# SIM3U166_B register map
File version: 1
CPU: 
Registers are 32-bit, read-write, reset 0x0 unless marked. A register's access mark holds for its fields unless they carry their own. Offsets are from the block's base; [hi:lo] are bit positions; {n}, {i} and the like mark numbered series; 'fields as' and 'values as' point back to an identical list.

## USB_0
Base 0x40018000
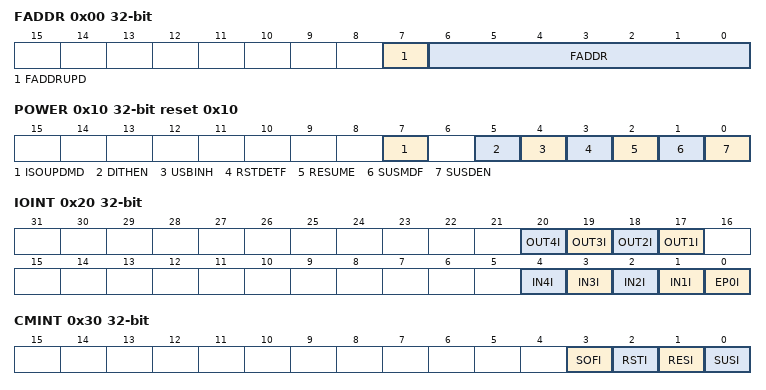
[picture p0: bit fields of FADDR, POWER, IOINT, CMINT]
0x00 FADDR — Function Address
  [7] FADDRUPD ro — Function Address Update.
    0=NOT_SET (The last address written to FADDR is in effect.); 1=SET (The last address written to FADDR is not yet in effect.)
  [6:0] FADDR — Function Address.
0x10 POWER reset 0x10 — Power Control
  [7] ISOUPDMD — ISO Update Mode.
    0=SEND_ON_IN (When software writes IPRDYI = 1, USB will send the packet when the next IN token is received.); 1=SEND_ON_SOF (When software writes IPRDYI = 1, USB will wait for a SOF token before sending the packet. If an IN token is received before a SOF token, USB will send a zero-length data packet.)
  [5] DITHEN — USB Dither Enable.
    0=DISABLED (Disable automatic USB dithering.); 1=ENABLED (Enable automatic USB dithering.)
  [4] USBINH — USB Inhibit.
    0=INACTIVE (Enable the USB module.); 1=ACTIVE (USB module inhibited. All USB traffic is ignored.)
  [3] RSTDETF ro — Reset Detect Flag.
    0=NOT_SET (Reset signaling is not present on the bus.); 1=SET (Reset signaling detected on the bus.)
  [2] RESUME — Force Resume.
    0=STOP; 1=GENERATE
  [1] SUSMDF ro — Suspend Mode Flag.
    0=NOT_SET (The USB module is not in suspend mode.); 1=SET (The USB module is in suspend mode.)
  [0] SUSDEN — Suspend Detection Enable.
    0=DISABLED (Disable suspend detection. The USB module will ignore suspend signaling on the bus.); 1=ENABLED (Enable suspend detection. The USB module will enter suspend mode if it detects suspend signalling on the bus.)
0x20 IOINT — IN/OUT Endpoint Interrupt Flags
  [n+16] OUT{n}I (n=1..4) — OUT Endpoint {n} Interrupt Flag.
    0=NOT_SET (Read: OUT Endpoint {n} interrupt has not occurred. Write: No effect.); 1=SET (Read: OUT Endpoint {n} interrupt occurred. Write: Clear the interrupt.)
  [n] IN{n}I (n=1..4) — IN Endpoint {n} Interrupt Flag.
    0=NOT_SET (Read: IN Endpoint {n} interrupt has not occurred. Write: No effect.); 1=SET (Read: IN Endpoint {n} interrupt occurred. Write: Clear the interrupt.)
  [0] EP0I — Endpoint 0 Interrupt Flag.
    0=NOT_SET (Read: Endpoint 0 interrupt has not occurred. Write: No effect.); 1=SET (Read: Endpoint 0 interrupt occurred. Write: Clear the interrupt.)
0x30 CMINT — Common Interrupt Flags
  [3] SOFI — Start of Frame Interrupt Flag.
    0=NOT_SET (Read: SOF interrupt has not occurred. Write: No effect.); 1=SET (Read: SOF interrupt occurred. Write: Clear the interrupt.)
  [2] RSTI — Reset Interrupt Flag.
    0=NOT_SET (Read: Reset interrupt has not occurred. Write: No effect.); 1=SET (Read: Reset interrupt occurred. Write: Clear the interrupt.)
  [1] RESI — Resume Interrupt Flag.
    0=NOT_SET (Read: Resume interrupt has not occurred. Write: No effect.); 1=SET (Read: Resume interrupt occurred. Write: Clear the interrupt.)
  [0] SUSI — Suspend Interrupt Flag.
    0=NOT_SET (Read: Suspend interrupt has not occurred. Write: No effect.); 1=SET (Read: Suspend interrupt occurred. Write: Clear the interrupt.)
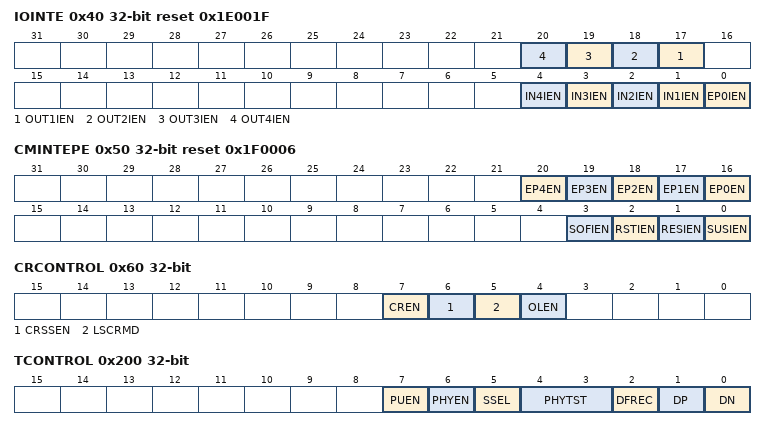
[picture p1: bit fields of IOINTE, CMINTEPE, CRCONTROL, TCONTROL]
0x40 IOINTE reset 0x1E001F — IN/OUT Endpoint Interrupt Control
  [n+16] OUT{n}IEN (n=1..4) — OUT Endpoint {n} Interrupt Enable.
    0=DISABLED (Disable the OUT Endpoint {n} interrupt.); 1=ENABLED (Enable the OUT Endpoint {n} interrupt.)
  [n] IN{n}IEN (n=1..4) — IN Endpoint {n} Interrupt Enable.
    0=DISABLED (Disable the IN Endpoint {n} interrupt.); 1=ENABLED (Enable the IN Endpoint {n} interrupt.)
  [0] EP0IEN — Endpoint 0 Interrupt Enable.
    0=DISABLED (Disable the Endpoint 0 interrupt.); 1=ENABLED (Enable the Endpoint 0 interrupt.)
0x50 CMINTEPE reset 0x1F0006 — Common Interrupt and Endpoint Control
  [n+16] EP{n}EN (n=0..4) — Endpoint {n} Enable.
    0=DISABLED (Disable Endpoint {n} (no NACK, ACK, or STALL on the USB network).); 1=ENABLED (Enable Endpoint {n} (normal).)
  [3] SOFIEN — Start of Frame Interrupt Enable.
    0=DISABLED (Disable the SOF interrupt.); 1=ENABLED (Enable the SOF interrupt.)
  [2] RSTIEN — Reset Interrupt Enable.
    0=DISABLED (Disable the Reset interrupt.); 1=ENABLED (Enable the Reset interrupt.)
  [1] RESIEN — Resume Interrupt Enable.
    0=DISABLED (Disable the Resume interrupt.); 1=ENABLED (Enable the Resume interrupt.)
  [0] SUSIEN — Suspend Interrupt Enable.
    0=DISABLED (Disable the Suspend interrupt.); 1=ENABLED (Enable the Suspend interrupt.)
0x60 CRCONTROL — Clock Recovery Control
  [7] CREN — Clock Recovery Enable.
    0=DISABLED (Disable clock recovery.); 1=ENABLED (Enable clock recovery.)
  [6] CRSSEN — Clock Recovery Single Step Enable.
    0=DISABLED (Normal calibration mode.); 1=ENABLED (Single step mode.)
  [5] LSCRMD — Low Speed Clock Recovery Mode.
    0=FULL_SPEED (Full Speed Mode.); 1=LOW_SPEED (Low Speed Mode.)
  [4] OLEN — Oscillator Open-Loop Mode Enable.
    0=DISABLED (Do not freeze the USB oscillator output frequency (closed loop mode).); 1=ENABLED (Freeze the USB oscillator output frequency (open loop mode).)
0x70 FRAME — Frame Number
  [10:0] FRAMENUM ro — Frame Number.
0x200 TCONTROL — Transceiver Control
  [7] PUEN — Internal Pull-up Resistor Enable.
    0=DISABLED (Disable the internal pull-up resistor (device effectively detached from the USB network).); 1=ENABLED (Enable the internal pull-up resistor when VBUS is present (device is attached to the USB network).)
  [6] PHYEN — Physical Layer Enable.
    0=DISABLED (Disable the USB physical layer Transceiver (suspend).); 1=ENABLED (Enable the USB physical layer Transceiver (normal).)
  [5] SSEL — USB Speed Select.
    0=LOW_SPEED (USB operates as a Low Speed device. If enabled, the internal pull-up resistor appears on the D- line.); 1=FULL_SPEED (USB operates as a Full Speed device. If enabled, the internal pull-up resistor appears on the D+ line.)
  [4:3] PHYTST — Physical Layer Test.
    0=MODE0 (Mode 0: Normal (non-test mode) (D+ = X, D- = X).); 1=MODE1 (Mode 1: Differential 1 Forced (D+ = 1, D- = 0).); 2=MODE2 (Mode 2: Differential 0 Forced (D+ = 0, D- = 1).); 3=MODE3 (Mode 3: Single-Ended 0 Forced (D+ = 0, D- = 0).)
  [2] DFREC ro — Differential Receiver State.
    0=DIFF_0 (Differential 0 signalling is present on the bus.); 1=DIFF_1 (Differential 1 signalling is present on the bus.)
  [1] DP ro — D+ Signal State.
    0=LOGIC_0 (D+ signal currently at logic 0.); 1=LOGIC_1 (D+ signal currently at logic 1.)
  [0] DN ro — D- Signal State.
    0=LOGIC_0 (D- signal currently at logic 0.); 1=LOGIC_1 (D- signal currently at logic 1.)
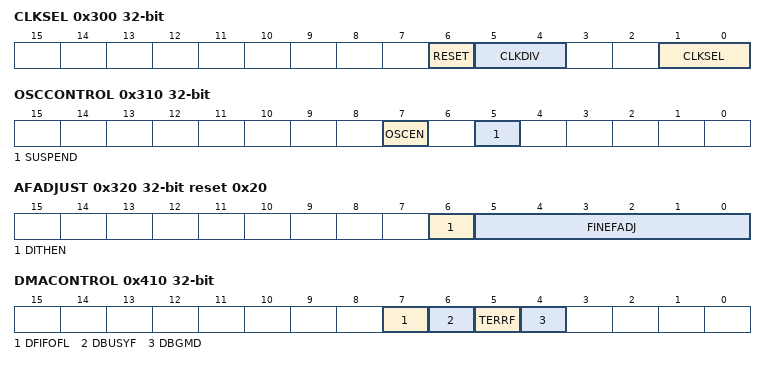
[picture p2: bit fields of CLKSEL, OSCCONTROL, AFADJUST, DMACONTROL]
0x300 CLKSEL — Module Clock Select
  [6] RESET wo — USB Reset.
    0=NOT_SET (Do not reset the USB module.); 1=SET (Reset the USB module.)
  [5:4] CLKDIV — USB Clock Divider.
    0=DIV1 (The USB module uses the selected input clock divided by 1.); 1=DIV2 (The USB module uses the selected input clock divided by 2.); 2=DIV4 (The USB module uses the selected input clock divided by 4.); 3=DIV8 (The USB module uses the selected input clock divided by 8.)
  [1:0] CLKSEL — USB Clock Select.
    0=USBNOSC (Select the USB Oscillator as the USB clock.); 1=PLLNOSC (Select the PLL output as the USB clock.); 2=EXTOSCN (Select the External Oscillator output (EXTOSCn) as the USB clock.)
0x310 OSCCONTROL — Oscillator Control
  [7] OSCEN — USB Oscillator Enable.
    0=DISABLED (Disable the USB oscillator.); 1=ENABLED (Enable the USB oscillator.)
  [5] SUSPEND — USB Oscillator Suspend.
    0=DISABLED (The USB oscillator is not suspended.); 1=ENABLED (Suspend the USB oscillator.)
0x320 AFADJUST reset 0x20 — Oscillator Additional Frequency Adjust
  [6] DITHEN — USB Oscillator Dithering Enable.
    0=DISABLED (Disable USB oscillator dithering.); 1=ENABLED (Enable USB oscillator dithering.)
  [5:0] FINEFADJ — USB Oscillator Fine Output Frequency Adjust.
0x330 FADJUST reset 0x40 — Oscillator Frequency Adjust
  [6:0] FADJ — Oscillator Output Frequency Adjust.
0x400 DMAFIFO read-has-side-effects — DMA Data FIFO Access
  [31:0] DMAFIFO — DMA Data FIFO Access.
0x410 DMACONTROL
  [7] DFIFOFL — USB DMA Buffer Flush Control.
    1=SET (Flush the USB DMA buffer.)
  [6] DBUSYF ro — USB DMA Busy Flag.
    0=NOT_SET (The DMA buffer is not busy.); 1=SET (The DMA buffer is busy reading or writing an 8-word packet.)
  [5] TERRF — Timeout Error Flag.
    0=NOT_SET (A timeout error has not occurred.); 1=SET (A timeout error occurred.)
  [4] DBGMD — USB DMA Debug Mode.
    0=RUN (The USB module will continue to operate while the core is halted in debug mode.); 1=HALT (A debug breakpoint will prevent the USB DMA buffer from transferring data to and from the USB FIFOs when the core is halted.)
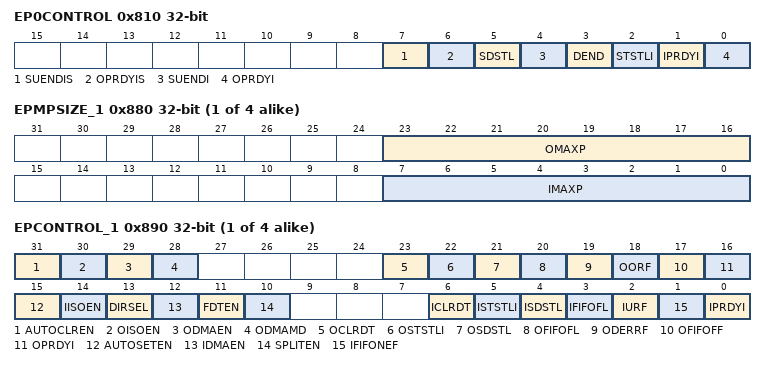
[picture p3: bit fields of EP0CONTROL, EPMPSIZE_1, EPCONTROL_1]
0x810 EP0CONTROL — Endpoint 0 Control
  [7] SUENDIS — Serviced Setup End Interrupt Flag.
    0=NOT_SET (Setup end has not been serviced.); 1=SET (Setup end has been serviced.)
  [6] OPRDYIS — Serviced Out Packet Ready Interrupt Flag.
    0=NOT_SET (The out packet has not been processed.); 1=SET (The out packet has been received and accepted.)
  [5] SDSTL — Send Stall.
    0=NOT_SET (The STALL handshake has been transmitted or not triggered.); 1=SET (Initiate a STALL condition.)
  [4] SUENDI ro — Setup End Interrupt Flag.
    0=NOT_SET (The current packet is not the last packet of setup.); 1=SET (The current packet is the last packet of setup.)
  [3] DEND — Data End.
    0=NOT_SET (The current packet is not the last packet of the transfer.); 1=SET (The current packet is the last packet of the transfer.)
  [2] STSTLI — Sent Stall Interrupt Flag.
    0=NOT_SET (Read: A STALL handshake has not been sent or is cleared. Write: Clear the interrupt.); 1=SET (Read: STALL handshake sent. Write: No effect.)
  [1] IPRDYI — IN Packet Ready Indicator.
    0=NOT_SET (A packet is not ready for transmission to host.); 1=SET (A packet is ready for transmission to host.)
  [0] OPRDYI ro — OUT Packet Ready Interrupt Flag.
    0=NOT_SET (A packet is not available.); 1=SET (A packet is available.)
0x820 EP0COUNT — Endpoint 0 Data Count
  [6:0] COUNT ro — Endpoint 0 OUT Data Count.
0x830 EP0FIFO read-has-side-effects — Endpoint 0 Data FIFO Access
  [31:0] FIFO — Endpoint 0 Data FIFO.
{0x800+0x80*i} EPMPSIZE_{i} (i=1..4) — Endpoint Maximum Packet Size
  [23:16] OMAXP — OUT Maximum Packet Size.
  [7:0] IMAXP — IN Maximum Packet Size.
{0x810+0x80*i} EPCONTROL_{i} (i=1..4) — Endpoint Control
  [31] AUTOCLREN — OUT Endpoint OPRDYI Auto-Clear Enable.
    0=DISABLED (The OPRDYI bit is not automatically cleared by hardware.); 1=ENABLED (The OPRDYI bit is automatically cleared by hardware.)
  [30] OISOEN — OUT Isochronous Transfer Enable.
    0=BULK_INT (Configure the endpoint for Bulk/Interrupt transfers.); 1=ISO (Configure the endpoint for Isochronous transfers.)
  [29] ODMAEN — OUT Endpoint DMA Enable.
    0=DISABLED (Disable the DMA request for the OUT endpoint.); 1=ENABLED (Enable the DMA request for the OUT endpoint.)
  [28] ODMAMD — OUT Endpoint DMA Mode.
    0=AUTO_DMA (Automatic DMA service is requested on the last packet of the transfer until less than four bytes remain in the packet. At this time, an interrupt is generated. The firmware must read or write the last few bytes of the packet, if any remain.); 1=NO_DMA (No DMA service is requested on the last packet of the transfer. When the DMA recognizes the last packet, an interrupt is generated. The firmware must handle the entirety of the last packet.)
  [23] OCLRDT — OUT Clear Data Toggle.
    0=NO_RESET (Do not reset the OUT data toggle.); 1=RESET (Reset the OUT data toggle.)
  [22] OSTSTLI — OUT Sent Stall Interrupt Flag.
    0=NOT_SET (Read: A stall condition has not been sent since this bit was last cleared. Write: Clear the interrupt.); 1=SET (Read: A stall condition has been sent since this bit was last cleared. Write: No effect.)
  [21] OSDSTL — OUT Send Stall.
    0=STOP (Stop sending a stall.); 1=SEND (Generate a stall.)
  [20] OFIFOFL — OUT FIFO Flush.
    1=SET (Flush the OUT FIFO.)
  [19] ODERRF — OUT Data Error Flag.
    0=NOT_SET (A CRC or bit-stuff error has not occurred.); 1=SET (A CRC or bit-stuff error occurred.)
  [18] OORF — OUT FIFO Overrun Flag.
    0=NOT_SET (No data overrun.); 1=SET (A data packet was lost because of a full FIFO since this flag was last cleared.)
  [17] OFIFOFF — OUT FIFO Full.
    0=NOT_SET (The OUT endpoint FIFO is not full.); 1=SET (The OUT endpoint FIFO is full.)
  [16] OPRDYI — OUT Packet Ready.
    0=NOT_SET (A data packet is not available.); 1=SET (A data packet is available.)
  [15] AUTOSETEN — IN Endpoint IPRDYI Automatic Set Enable.
    0=DISABLED (The IPRDYI bit is not automatically set by hardware.); 1=ENABLED (The IPRDYI bit is automatically set by hardware.)
  [14] IISOEN — IN Isochronous Transfer Enable.
    values as OISOEN
  [13] DIRSEL — Endpoint Direction Select.
    0=OUT (Select the endpoint direction as OUT.); 1=IN (Select the endpoint direction as IN.)
  [12] IDMAEN — IN Endpoint DMA Enable.
    0=DISABLED (Disable the DMA request for the IN endpoint.); 1=ENABLED (Enable the DMA request for the IN endpoint.)
  [11] FDTEN — Force Data Toggle Enable.
    0=DISABLED (The endpoint data toggle switches only when an ACK is received following a data packet transmission.); 1=ENABLED (The endpoint data toggle is forced to switch after every data packet is transmitted, regardless of ACK reception.)
  [10] SPLITEN — FIFO Split Enable.
    0=DISABLED (Do not split the endpoint FIFO.); 1=ENABLED (Split the endpoint FIFO.)
  [6] ICLRDT — IN Clear Data Toggle.
    0=NO_RESET (Do not reset the IN data toggle.); 1=RESET (Reset the IN data toggle.)
  [5] ISTSTLI — IN Sent Stall Interrupt Flag.
    values as OSTSTLI
  [4] ISDSTL — IN Send Stall.
    0=NOT_SET (Stop sending a stall.); 1=SET (Generate a stall.)
  [3] IFIFOFL — IN FIFO Flush.
    1=SET (Flush the IN FIFO.)
  [2] IURF — IN FIFO Underrun Flag.
    0=NOT_SET (Underrun has not occurred.); 1=SET (Underrun occurred.)
  [1] IFIFONEF — IN FIFO Not Empty Flag.
    0=NOT_SET (The IN Endpoint FIFO is empty.); 1=SET (The IN Endpoint FIFO contains one or more packets.)
  [0] IPRDYI — IN Packet Ready Indicator.
    0=NOT_SET (The packet has been sent or there is an open FIFO slot.); 1=SET (A packet is loaded in the FIFO.)
{0x820+0x80*i} EPCOUNT_{i} (i=1..4) — Endpoint Data Count
  [9:0] COUNT ro — Endpoint OUT Data Count.
{0x830+0x80*i} EPFIFO_{i} read-has-side-effects (i=1..4) — Endpoint Data FIFO Access
  [31:0] FIFO — Endpoint Data FIFO.
